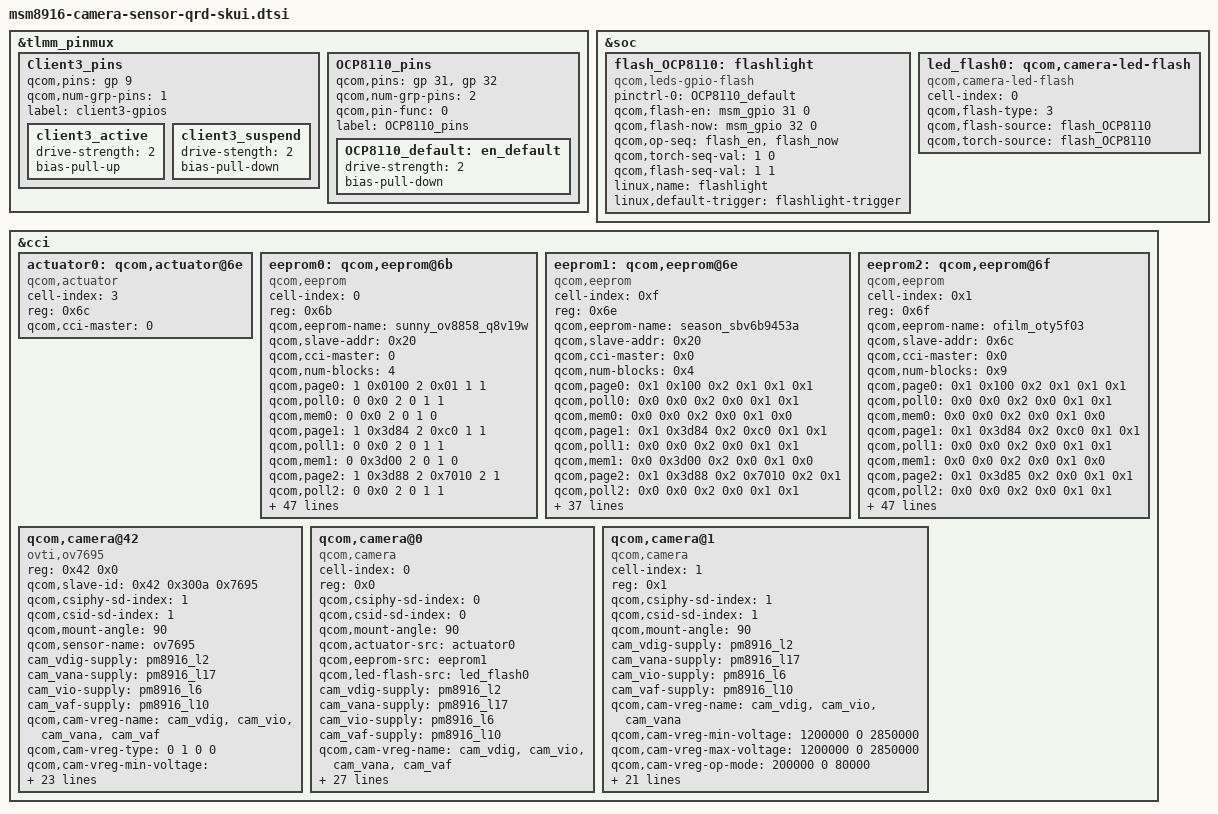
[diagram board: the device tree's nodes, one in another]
/* Copyright (c) 2020, The Linux Foundation. All rights reserved.
*  Copyright (c) 2020, the_shahnawaz_sheikh (sheikhshahnawaz41299).
*
* This program is free software; you can redistribute it and/or modify
* it under the terms of the GNU General Public License version 2 and
* only version 2 as published by the Free Software Foundation.
*
* This program is distributed in the hope that it will be useful,
* but WITHOUT ANY WARRANTY; without even the implied warranty of
* MERCHANTABILITY or FITNESS FOR A PARTICULAR PURPOSE.  See the
* GNU General Public License for more details.
*/

&tlmm_pinmux {
    
	Client3_pins {
				qcom,pins = <&gp 9>;
				qcom,num-grp-pins = <1>;
				label = "client3-gpios";

				client3_active: client3_active {
					drive-strength = <2>;
					bias-pull-up;
				};

				client3_suspend: client3_suspend {
					drive-stength = <2>;
					bias-pull-down;
				};
	};
	
	OCP8110_pins {
		qcom,pins = <&gp 31>, <&gp 32>;
		qcom,num-grp-pins = <2>;
		qcom,pin-func = <0>;
		label = "OCP8110_pins";
		OCP8110_default: en_default {
			  drive-strength = <2>;
			  bias-pull-down;
		};
	};
};

&soc {
	flash_OCP8110:flashlight {
		compatible = "qcom,leds-gpio-flash";
		status = "okay";
		pinctrl-names = "flash_default";
		pinctrl-0 = <&OCP8110_default>;
		qcom,flash-en = <&msm_gpio 31 0>;
		qcom,flash-now = <&msm_gpio 32 0>;
		qcom,op-seq = "flash_en", "flash_now";
		qcom,torch-seq-val = <1 0>;
		qcom,flash-seq-val = <1 1>;
		linux,name = "flashlight";
		linux,default-trigger = "flashlight-trigger";
	};

	led_flash0: qcom,camera-led-flash {
		cell-index = <0>;
		compatible = "qcom,camera-led-flash";
		qcom,flash-type = <3>;
		qcom,flash-source = <&flash_OCP8110>;
		qcom,torch-source = <&flash_OCP8110>;
	};
};

&cci {

	actuator0: qcom,actuator@6e {
		cell-index = <3>;
		reg = <0x6c>;
		compatible = "qcom,actuator";
		qcom,cci-master = <0>;
	};
	
	/delete-node/ qcom,eeprom@6b;

	eeprom0: qcom,eeprom@6b{
		cell-index = <0>;
		reg = <0x6b>;
		qcom,eeprom-name = "sunny_ov8858_q8v19w";
		compatible = "qcom,eeprom";
		qcom,slave-addr = <0x20>;
		qcom,cci-master = <0>;
		qcom,num-blocks = <4>;

		qcom,page0 = <1 0x0100 2 0x01 1 1>;
		qcom,poll0 = <0 0x0 2 0 1 1>;
		qcom,mem0 = <0 0x0 2 0 1 0>;
		qcom,page1 = <1 0x3d84 2 0xc0 1 1>;
		qcom,poll1 = <0 0x0 2 0 1 1>;
		qcom,mem1 = <0 0x3d00 2 0 1 0>;
		qcom,page2 = <1 0x3d88 2 0x7010 2 1>;
		qcom,poll2 = <0 0x0 2 0 1 1>;
		qcom,mem2 = <0 0x3d00 2 0 1 0>;
		qcom,page3 = <1 0x3d8a 2 0x7184 2 1>;
		qcom,pageen3 = <1 0x3d81 2 0x01 1 10>;
		qcom,poll3 = <0 0x0 2 0 1 1>;
		qcom,mem3 = <0x175 0x7010 0x2 0x0 0x1 0x1>;
		qcom,page4 = <1 0x3d84 2 0xc0 1 1>;
		qcom,poll4 = <0 0x0 2 0 1 1>;
		qcom,mem4 = <0 0x0 2 0 1 0>;
		qcom,page5 = <1 0x3d85 2 0x10 1 1>;
		qcom,poll5 = <0 0x0 2 0 1 1>;
		qcom,mem5 = <0 0x0 2 0 1 0>;
		qcom,page6 = <1 0x3d86 2 0x1f 1 1>;
		qcom,pageen6 = <1 0x3d81 2 0x01 1 10>;
		qcom,poll6 = <0 0x0 2 0 1 1>;
		qcom,mem6 = <16 0x3d00 2 0 1 0>;

		cam_vdig-supply = <&pm8916_l2>;
		cam_vana-supply = <&pm8916_l17>;
		cam_vio-supply = <&pm8916_l6>;
		cam_vaf-supply = <&pm8916_l10>;
		qcom,cam-vreg-name = "cam_vdig", "cam_vio", "cam_vana",
							"cam_vaf";
		qcom,cam-vreg-min-voltage = <1200000 0 2800000 2850000>;
		qcom,cam-vreg-max-voltage = <1200000 0 2850000 2900000>;
		qcom,cam-vreg-op-mode = <200000 0 80000 100000>;
		pinctrl-names = "cam_default", "cam_suspend";
		pinctrl-0 = <&cam_sensor_mclk0_default &cam_sensor_rear_default>;
		pinctrl-1 = <&cam_sensor_mclk0_sleep &cam_sensor_rear_sleep>;
		gpios = <&msm_gpio 26 0>,
			<&msm_gpio 35 0>,
			<&msm_gpio 34 0>;
		qcom,gpio-reset = <1>;
		qcom,gpio-standby = <2>;
		qcom,gpio-req-tbl-num = <0 1 2 >;
		qcom,gpio-req-tbl-flags = <1 0 0>;
		qcom,gpio-req-tbl-label = "CAMIF_MCLK",
			"CAM_RESET1",
			"CAM_STANDBY";

		qcom,cam-power-seq-type = "sensor_vreg",
			"sensor_gpio", "sensor_gpio",
			"sensor_clk";
		qcom,cam-power-seq-val = "cam_vaf",
			"sensor_gpio_reset",
			"sensor_gpio_standby",
			"sensor_cam_mclk" ;
		qcom,cam-power-seq-cfg-val = <1 1 1 23880000>;
		qcom,cam-power-seq-delay = <1 10 10 5>;

		clocks = <&clock_gcc clk_mclk0_clk_src>,
			<&clock_gcc clk_gcc_camss_mclk0_clk>;
		clock-names = "cam_src_clk", "cam_clk";
		qcom,cam-vreg-type = <0x0 0x1 0x0 0x0>;
	};
	
	eeprom1: qcom,eeprom@6e {
				cell-index = <0xf>;
				reg = <0x6e>;
				qcom,eeprom-name = "season_sbv6b9453a";
				compatible = "qcom,eeprom";
				qcom,slave-addr = <0x20>;
				qcom,cci-master = <0x0>;
				qcom,num-blocks = <0x4>;
				qcom,page0 = <0x1 0x100 0x2 0x1 0x1 0x1>;
				qcom,poll0 = <0x0 0x0 0x2 0x0 0x1 0x1>;
				qcom,mem0 = <0x0 0x0 0x2 0x0 0x1 0x0>;
				qcom,page1 = <0x1 0x3d84 0x2 0xc0 0x1 0x1>;
				qcom,poll1 = <0x0 0x0 0x2 0x0 0x1 0x1>;
				qcom,mem1 = <0x0 0x3d00 0x2 0x0 0x1 0x0>;
				qcom,page2 = <0x1 0x3d88 0x2 0x7010 0x2 0x1>;
				qcom,poll2 = <0x0 0x0 0x2 0x0 0x1 0x1>;
				qcom,mem2 = <0x0 0x3d00 0x2 0x0 0x1 0x0>;
				qcom,page3 = <0x1 0x3d8a 0x2 0x7184 0x2 0x1>;
				qcom,pageen3 = <0x1 0x3d81 0x2 0x1 0x1 0xa>;
				qcom,poll3 = <0x0 0x0 0x2 0x0 0x1 0x1>;
				qcom,mem3 = <0x175 0x7010 0x2 0x0 0x1 0x1>;
				cam_vdig-supply = <&pm8916_l2>;
				cam_vana-supply = <&pm8916_l17>;
				cam_vio-supply = <&pm8916_l6>;
				cam_vaf-supply = <&pm8916_l10>;
				qcom,cam-vreg-name = "cam_vdig", "cam_vio", "cam_vana", "cam_vaf";
				qcom,cam-vreg-type = <0 1 0 0>;
				qcom,cam-vreg-min-voltage = <1200000 0 2800000 2850000>;
				qcom,cam-vreg-max-voltage = <1200000 0 2850000 2900000>;
				qcom,cam-vreg-op-mode = <200000 0 80000 100000>;
				pinctrl-names = "cam_default", "cam_suspend";
				pinctrl-0 = <&cam_sensor_mclk0_default &cam_sensor_rear_default>;
				pinctrl-1 = <&cam_sensor_mclk0_sleep &cam_sensor_rear_sleep>;
				gpios = <&msm_gpio 26 0>,
				         <&msm_gpio 35 0>,
						 <&msm_gpio 34 0>;
				qcom,gpio-reset = <1>;
				qcom,gpio-standby = <2>;
				qcom,gpio-req-tbl-num = <0 1 2>;
				qcom,gpio-req-tbl-flags = <1 0 0>;
				qcom,gpio-req-tbl-label = "CAMIF_MCLK", "CAM_RESET1", "CAM_STANDBY";
				qcom,cam-power-seq-type = "sensor_vreg", "sensor_gpio", "sensor_gpio", "sensor_clk";
				qcom,cam-power-seq-val = "cam_vaf", "sensor_gpio_reset", "sensor_gpio_standby", "sensor_cam_mclk";
				qcom,cam-power-seq-cfg-val = <1 1 1 23880000>;
				qcom,cam-power-seq-delay = <1 10 10 5>;
				clocks = <&clock_gcc clk_mclk0_clk_src>,
			                <&clock_gcc clk_gcc_camss_mclk0_clk>;
				clock-names = "cam_src_clk", "cam_clk";
			};

			eeprom2: qcom,eeprom@6f {
				cell-index = <0x1>;
				reg = <0x6f>;
				qcom,eeprom-name = "ofilm_oty5f03";
				compatible = "qcom,eeprom";
				qcom,slave-addr = <0x6c>;
				qcom,cci-master = <0x0>;
				qcom,num-blocks = <0x9>;
				qcom,page0 = <0x1 0x100 0x2 0x1 0x1 0x1>;
				qcom,poll0 = <0x0 0x0 0x2 0x0 0x1 0x1>;
				qcom,mem0 = <0x0 0x0 0x2 0x0 0x1 0x0>;
				qcom,page1 = <0x1 0x3d84 0x2 0xc0 0x1 0x1>;
				qcom,poll1 = <0x0 0x0 0x2 0x0 0x1 0x1>;
				qcom,mem1 = <0x0 0x0 0x2 0x0 0x1 0x0>;
				qcom,page2 = <0x1 0x3d85 0x2 0x0 0x1 0x1>;
				qcom,poll2 = <0x0 0x0 0x2 0x0 0x1 0x1>;
				qcom,mem2 = <0x0 0x0 0x2 0x0 0x1 0x1>;
				qcom,page3 = <0x1 0x3d86 0x2 0xf 0x1 0x1>;
				qcom,poll3 = <0x0 0x0 0x2 0x0 0x1 0x1>;
				qcom,mem3 = <0x0 0x0 0x2 0x0 0x1 0x1>;
				qcom,page4 = <0x1 0x3d81 0x2 0x1 0x1 0x1>;
				qcom,poll4 = <0x0 0x0 0x2 0x0 0x1 0x1>;
				qcom,mem4 = <0xf 0x3d00 0x2 0x0 0x1 0x0>;
				qcom,page5 = <0x1 0x3d84 0x2 0xc0 0x1 0x1>;
				qcom,poll5 = <0x0 0x0 0x2 0x0 0x1 0x1>;
				qcom,mem5 = <0x0 0x0 0x2 0x0 0x1 0x1>;
				qcom,page6 = <0x1 0x3d85 0x2 0x10 0x1 0x1>;
				qcom,poll6 = <0x0 0x0 0x2 0x0 0x1 0x1>;
				qcom,mem6 = <0x0 0x0 0x2 0x0 0x1 0x1>;
				qcom,page7 = <0x1 0x3d86 0x2 0x1f 0x1 0x1>;
				qcom,poll7 = <0x0 0x0 0x2 0x0 0x1 0x1>;
				qcom,mem7 = <0x0 0x0 0x2 0x0 0x1 0x0>;
				qcom,page8 = <0x1 0x3d81 0x2 0x1 0x1 0x1>;
				qcom,poll8 = <0x0 0x0 0x2 0x0 0x1 0x1>;
				qcom,mem8 = <0xf 0x3d00 0x2 0x0 0x1 0x0>;
				cam_vdig-supply = <&pm8916_l2>;
				cam_vana-supply = <&pm8916_l17>;
				cam_vio-supply = <&pm8916_l6>;
				qcom,cam-vreg-name = "cam_vdig", "cam_vio", "cam_vana";
				qcom,cam-vreg-type = <0 1 0>;
				qcom,cam-vreg-min-voltage = <1200000 0 2850000>;
				qcom,cam-vreg-max-voltage = <1200000 0 2850000>;
				qcom,cam-vreg-op-mode = <200000 0 80000>;
				pinctrl-names = "cam_default", "cam_suspend";
				pinctrl-0 = <&cam_sensor_mclk1_default &cam_sensor_front_default>;
				pinctrl-1 = <&cam_sensor_mclk1_sleep &cam_sensor_front_sleep>;
				gpios = <&msm_gpio 27 0>,
				         <&msm_gpio 28 0>,
						 <&msm_gpio 33 0>;
				qcom,gpio-reset = <0x1>;
				qcom,gpio-standby = <0x2>;
				qcom,gpio-req-tbl-num = <0 1 2>;
				qcom,gpio-req-tbl-flags = <1 0 0>;
				qcom,gpio-req-tbl-label = "CAMIF_MCLK", "SCAM_RESET", "SCAM_STANDBY";
				qcom,cam-power-seq-type = "sensor_gpio", "sensor_gpio", "sensor_clk";
				qcom,cam-power-seq-val = "sensor_gpio_standby", "sensor_gpio_reset", "sensor_cam_mclk";
				qcom,cam-power-seq-cfg-val = <1 1 23880000>;
				qcom,cam-power-seq-delay = <5 10 10>;
				clocks = <&clock_gcc clk_mclk0_clk_src>,
			                <&clock_gcc clk_gcc_camss_mclk0_clk>;
				clock-names = "cam_src_clk", "cam_clk";
			};


	qcom,camera@42 {
		compatible = "ovti,ov7695";
		reg = <0x42 0x0>;
		qcom,slave-id = <0x42 0x300a 0x7695>;
		qcom,csiphy-sd-index = <1>;
		qcom,csid-sd-index = <1>;
		qcom,mount-angle = <90>;
		qcom,sensor-name = "ov7695";
		cam_vdig-supply = <&pm8916_l2>;
		cam_vana-supply = <&pm8916_l17>;
		cam_vio-supply = <&pm8916_l6>;
		cam_vaf-supply = <&pm8916_l10>;
		qcom,cam-vreg-name = "cam_vdig", "cam_vio", "cam_vana",
							"cam_vaf";
		qcom,cam-vreg-type = <0 1 0 0>;
		qcom,cam-vreg-min-voltage = <1200000 0 2850000 2800000>;
		qcom,cam-vreg-max-voltage = <1200000 0 2850000 2800000>;
		qcom,cam-vreg-op-mode = <200000 0 80000 100000>;
		pinctrl-names = "cam_default", "cam_suspend";
		pinctrl-0 = <&cam_sensor_mclk1_default &cam_sensor_front_default>;
		pinctrl-1 = <&cam_sensor_mclk1_sleep &cam_sensor_front_sleep>;
		gpios = <&msm_gpio 27 0>,
			<&msm_gpio 28 0>,
			<&msm_gpio 33 0>;
		qcom,gpio-reset = <1>;
		qcom,gpio-standby = <2>;
		qcom,gpio-req-tbl-num = <0 1 2>;
		qcom,gpio-req-tbl-flags = <1 0 0>;
		qcom,gpio-req-tbl-label = "CAMIF_MCLK",
					"CAM_RESET",
					"CAM_STANDBY";
		qcom,csi-lane-assign = <0x4320>;
		qcom,csi-lane-mask = <0x3>;
		qcom,sensor-position = <1>;
		qcom,sensor-mode = <0>;
		qcom,cci-master = <0>;
		qcom,mclk-23880000;
		status = "ok";
		clocks = <&clock_gcc clk_mclk1_clk_src>,
				<&clock_gcc clk_gcc_camss_mclk1_clk>;
		clock-names = "cam_src_clk", "cam_clk";
	};

	qcom,camera@0 {
		cell-index = <0>;
		compatible = "qcom,camera";
		reg = <0x0>;
		qcom,csiphy-sd-index = <0>;
		qcom,csid-sd-index = <0>;
		qcom,mount-angle = <90>;
		qcom,actuator-src = <&actuator0>;
		qcom,eeprom-src = <&eeprom1>;
		qcom,led-flash-src = <&led_flash0>;
		cam_vdig-supply = <&pm8916_l2>;
		cam_vana-supply = <&pm8916_l17>;
		cam_vio-supply = <&pm8916_l6>;
		cam_vaf-supply = <&pm8916_l10>;
		qcom,cam-vreg-name = "cam_vdig", "cam_vio", "cam_vana",
							"cam_vaf";
		qcom,cam-vreg-min-voltage = <1200000 0 2850000 2800000>;
		qcom,cam-vreg-max-voltage = <1200000 0 2850000 2800000>;
		qcom,cam-vreg-op-mode = <200000 0 80000 100000>;
		pinctrl-names = "cam_default", "cam_suspend";
		pinctrl-0 = <&cam_sensor_mclk0_default &cam_sensor_rear_default &client3_active>;
		pinctrl-1 = <&cam_sensor_mclk0_sleep &cam_sensor_rear_sleep &client3_suspend>;
		gpios = <&msm_gpio 26 0>,
		         <&msm_gpio 35 0>,
				 <&msm_gpio 34 0>,
				 <&msm_gpio 120 0>,
				 <&msm_gpio 9 0>,
				 <&msm_gpio 20 0>;
		qcom,gpio-reset = <1>;
		qcom,gpio-standby = <2>;
		qcom,gpio-af-pwdm = <3>;
		qcom,gpio-req-tbl-num = <0 1 2 3 4 5>;
		qcom,gpio-req-tbl-flags = <1 0 0 0 0 0>;
		qcom,gpio-req-tbl-label = "CAMIF_MCLK", "CAM_RESET1", 
		                       "CAM_STANDBY", "CAM_AF_PWDM",
							   "CAM_ID", "CAM_VANA";
		qcom,sensor-position = <0>;
		qcom,sensor-mode = <0>;
		qcom,cci-master = <0>;
		qcom,mclk-23880000;
		status = "ok";
		clocks = <&clock_gcc clk_mclk0_clk_src>,
				<&clock_gcc clk_gcc_camss_mclk0_clk>;
		clock-names = "cam_src_clk", "cam_clk";
		qcom,gpio-camid = <4>;
		qcom,gpio-vana = <5>;
	};

	qcom,camera@1 {
		cell-index = <1>;
		compatible = "qcom,camera";
		reg = <0x1>;
		qcom,csiphy-sd-index = <1>;
		qcom,csid-sd-index = <1>;
		qcom,mount-angle = <90>;
		cam_vdig-supply = <&pm8916_l2>;
		cam_vana-supply = <&pm8916_l17>;
		cam_vio-supply = <&pm8916_l6>;
		cam_vaf-supply = <&pm8916_l10>;
		qcom,cam-vreg-name = "cam_vdig", "cam_vio", "cam_vana";
		qcom,cam-vreg-min-voltage = <1200000 0 2850000>;
		qcom,cam-vreg-max-voltage = <1200000 0 2850000>;
		qcom,cam-vreg-op-mode = <200000 0 80000>;
		pinctrl-names = "cam_default", "cam_suspend";
		pinctrl-0 = <&cam_sensor_mclk1_default &cam_sensor_front_default>;
		pinctrl-1 = <&cam_sensor_mclk1_sleep &cam_sensor_front_sleep>;
		gpios = <&msm_gpio 27 0>,
			<&msm_gpio 28 0>,
			<&msm_gpio 33 0>,
			<&msm_gpio 20 0>;
		qcom,gpio-reset = <1>;
		qcom,gpio-standby = <2>;
		qcom,gpio-req-tbl-num = <0 1 2 3>;
		qcom,gpio-req-tbl-flags = <1 0 0 0>;
		qcom,gpio-req-tbl-label = "CAMIF_MCLK",
			"CAM_RESET",
			"CAM_STANDBY",
		    "CAM_VANA";
		qcom,sensor-position = <1>;
		qcom,sensor-mode = <0>;
		qcom,cci-master = <0>;
		qcom,mclk-23880000;
		status = "ok";
		clocks = <&clock_gcc clk_mclk1_clk_src>,
				<&clock_gcc clk_gcc_camss_mclk1_clk>;
		clock-names = "cam_src_clk", "cam_clk";
		qcom,eeprom-src = <&eeprom2>;
		qcom,cam-vreg-type = <0 1 0>;
		qcom,gpio-vana = <3>;
	};
};

